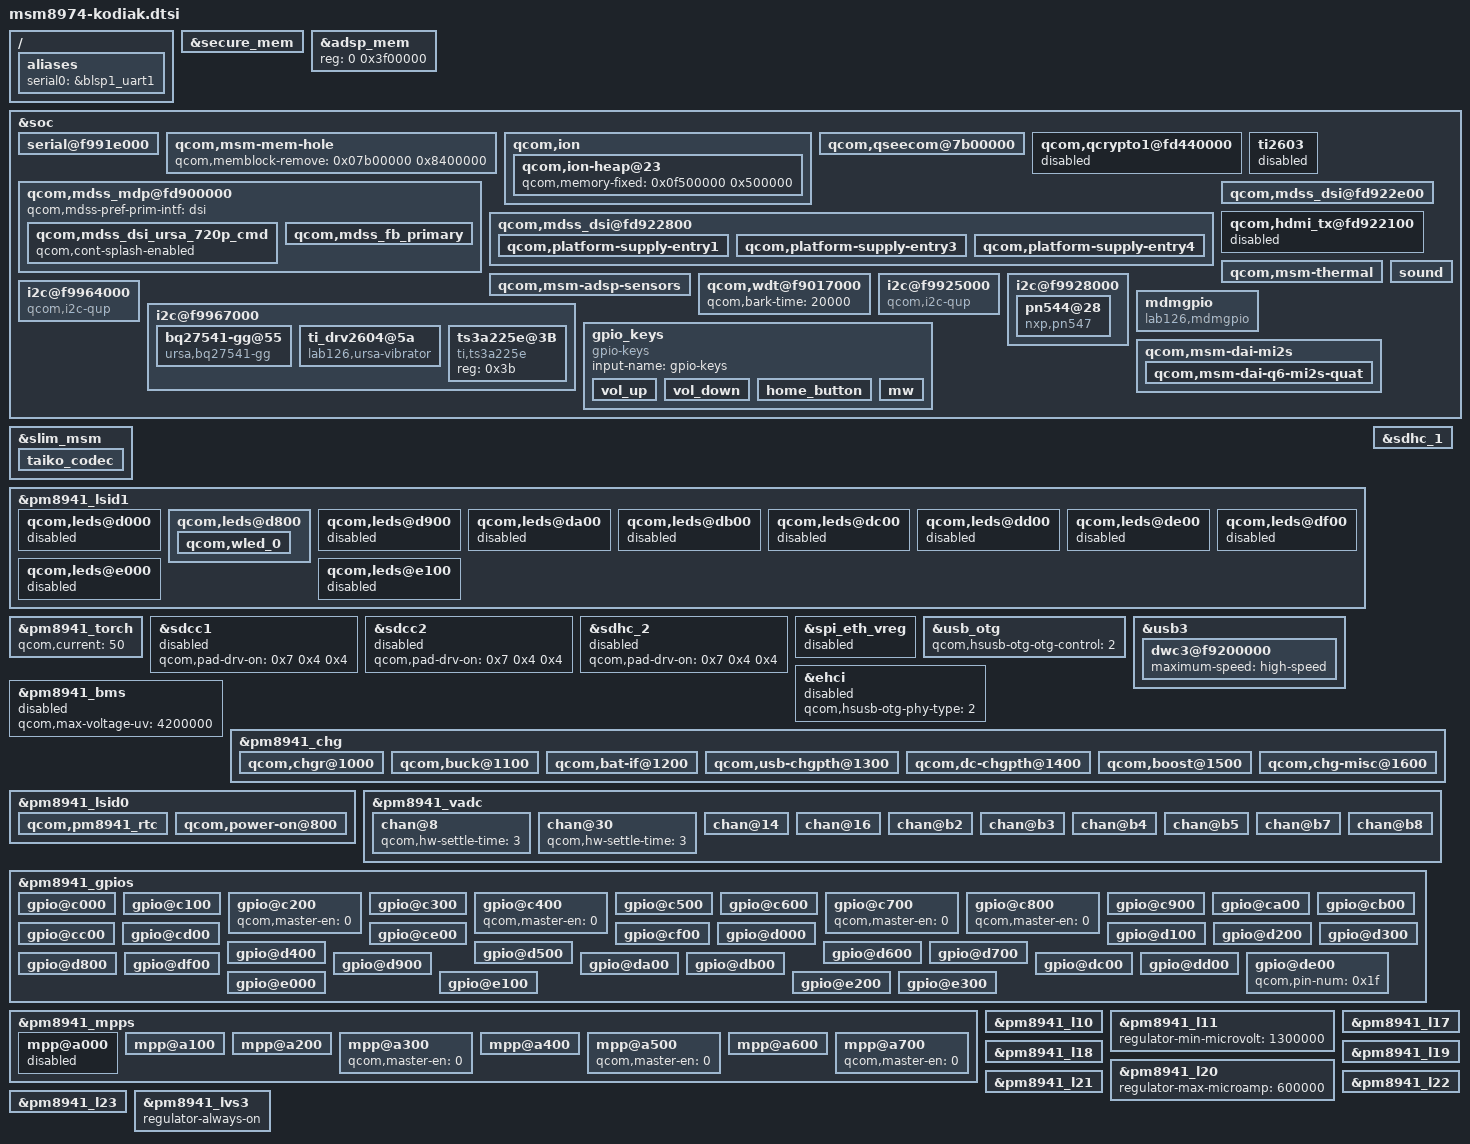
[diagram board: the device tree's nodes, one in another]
/* Copyright (c) 2012-2014, The Linux Foundation. All rights reserved.
 *
 * This program is free software; you can redistribute it and/or modify
 * it under the terms of the GNU General Public License version 2 and
 * only version 2 as published by the Free Software Foundation.
 *
 * This program is distributed in the hope that it will be useful,
 * but WITHOUT ANY WARRANTY; without even the implied warranty of
 * MERCHANTABILITY or FITNESS FOR A PARTICULAR PURPOSE.  See the
 * GNU General Public License for more details.
 */

/include/ "msm8974-camera-sensor-kodiak.dtsi"
/include/ "msm8974-leds.dtsi"
/include/ "msm8974-regulator.dtsi"
/include/ "dsi-panel-ursa-720p-cmd.dtsi"

/ {
	aliases {
		serial0 = &blsp1_uart1;
	};
};

&secure_mem {
	linux,reserve-region;
	reg = <0 0x9d00000>;
};

&adsp_mem {
	reg = <0 0x3f00000>;
};

&soc {
	serial@f991e000 {
		status = "ok";
		qcom,config-gpio = <2>;
		qcom,tx-gpio = <&msmgpio 4 0x00>;
		qcom,rx-gpio = <&msmgpio 5 0x00>;
	};

	qcom,msm-mem-hole {
		qcom,memblock-remove = <0x07b00000 0x8400000>; /* Address and Size of Hole */
	};

	qcom,ion {
		qcom,ion-heap@23 { /* OTHER PIL HEAP */
			qcom,memory-fixed = <0x0f500000 0x500000>;
		};
	};

	qcom,qseecom@7b00000 {
		/delete-property/ qcom,support-fde;
		/delete-property/ qcom,support-pfe;
		/delete-property/ qcom,file-encrypt-pipe-pair;
	};

	qcom,qcrypto1@fd440000 {
		status = "disabled";
	};

	ti2603 {
		status = "disabled";
	};

	qcom,mdss_mdp@fd900000 {
		qcom,mdss-pref-prim-intf = "dsi";

		qcom,mdss_dsi_ursa_720p_cmd {
			qcom,cont-splash-enabled;
		};

		qcom,mdss_fb_primary {
			qcom,memory-reservation-type = "EBI1";
			qcom,memory-reservation-size = <0x800000>;
		};
	};

	qcom,mdss_dsi@fd922800 {
		qcom,dsi-pref-prim-pan = <&dsi_ursa_720p_cmd>;
		qcom,platform-enable-gpio = <&msmgpio 58 0>;
		qcom,platform-touch-rst-gpio = <&msmgpio 60 0>;
		qcom,platform-lane-config = [00 00 00 00 00 00 00 01 97
			00 00 00 00 05 00 00 01 97
			00 00 00 00 0a 00 00 01 97
			00 00 00 00 0f 00 00 01 97
			00 c0 00 00 00 00 00 01 bb];
		vddio_panel-supply = <&pm8941_lvs2>;

		qcom,platform-supply-entry1 {
			qcom,supply-min-voltage = <3150000>;
			qcom,supply-max-voltage = <3150000>;
		};

		qcom,platform-supply-entry3 {
			qcom,supply-name = "vddio_panel";
			qcom,supply-min-voltage = <0>;
			qcom,supply-max-voltage = <0>;
			qcom,supply-enable-load = <0>;
			qcom,supply-disable-load = <0>;
			qcom,supply-pre-on-sleep = <0>;
			qcom,supply-post-on-sleep = <0>;
			qcom,supply-pre-off-sleep = <0>;
			qcom,supply-post-off-sleep = <0>;
		};

		qcom,platform-supply-entry4 {
			qcom,supply-name = "vdda";
			qcom,supply-min-voltage = <1200000>;
			qcom,supply-max-voltage = <1200000>;
			qcom,supply-enable-load = <100000>;
			qcom,supply-disable-load = <100>;
			qcom,supply-pre-on-sleep = <0>;
			qcom,supply-post-on-sleep = <0>;
			qcom,supply-pre-off-sleep = <0>;
			qcom,supply-post-off-sleep = <0>;
		};
	};

	qcom,mdss_dsi@fd922e00 {
		qcom,platform-lane-config = [00 00 00 00 00 00 00 01 97
			00 00 00 00 05 00 00 01 97
			00 00 00 00 0a 00 00 01 97
			00 00 00 00 0f 00 00 01 97
			00 c0 00 00 00 00 00 01 bb];
	};

	qcom,hdmi_tx@fd922100 {
		status = "disabled";
	};

	qcom,msm-thermal {
		qcom,limit-temp = <90>;
		qcom,core-limit-temp = <105>;
		qcom,core-temp-hysteresis = <15>;
	};

	qcom,msm-adsp-sensors {
		qcom,src-id = <11>;
		qcom,dst-id = <604>;
		qcom,ab = <32505856>;
		qcom,ib = <32505856>;
	};

	qcom,wdt@f9017000 {
		qcom,bark-time = <20000>;
	};

	i2c@f9925000 { /* BLSP-1 QUP-3 */
		cell-index = <3>;
		compatible = "qcom,i2c-qup";
		reg = <0xf9925000 0x1000>;
		#address-cells = <1>;
		#size-cells = <0>;
		reg-names = "qup_phys_addr";
		interrupts = <0 97 0>;
		interrupt-names = "qup_err_intr";
		qcom,i2c-bus-freq = <400000>;
		qcom,i2c-src-freq = <19200000>;
	};

	i2c@f9928000 { /* BLSP-1 QUP-6 */
		cell-index = <6>;
		qcom,i2c-src-freq = <50000000>;
		/delete-property/ qcom,master-id;
		/delete-property/ qcom,scl-gpio;
		/delete-property/ qcom,sda-gpio;

		pn544@28 {
			compatible = "nxp,pn547";
			reg = <0x28>;
			interrupt-parent = <&msmgpio>;
			interrupts = <59 0x2>, <86 0x3>;
			nxp,irq-gpio = <&msmgpio 59 0x00>;
			nxp,clk-req-gpio = <&msmgpio 86 0x00>;
			nxp,dload-gpio = <&pm8941_gpios 32 0x00>;
			nxp,enable-gpio = <&pm8941_gpios 7 0x00>;
			nxp,pvdd-supply = <&pm8941_l10>;
			nxp,pmuvcc-supply = <&pm8941_l9>;
		};
	};

	i2c@f9964000 { /* BLSP-2 QUP-2 */
		cell-index = <8>;
		compatible = "qcom,i2c-qup";
		reg = <0xf9964000 0x1000>;
		#address-cells = <1>;
		#size-cells = <0>;
		reg-names = "qup_phys_addr";
		interrupts = <0 102 0>;
		interrupt-names = "qup_err_intr";
		qcom,i2c-bus-freq = <400000>;
		qcom,i2c-src-freq = <50000000>;
	};

	i2c@f9967000 {
		bq27541-gg@55 {
			compatible = "ursa,bq27541-gg";
			reg = <0x55>;
			spmi-dev-container;
			ursa,use-voltage-soc = <0>;
			ursa,gg-snapshot-sec = <300>;
			ursa,gg-status-wake-sec = <3>;
			ursa,gg-status-sleep-real-sec = <1200>;
			ursa,info-shutoff-mv = <3250>;
			ursa,info-alt-shutoff-mv = <3100>;
			ursa,mib-charge-mv = <4350>;
			ursa,mib-capacity-mah = <2360>;
			ursa,mib-charge-rate = <7>;
			ursa,mib-taper-ma = <80>;
			ursa,limit-temp-hi-dk = <3332>;
			ursa,limit-temp-lo-dk = <2732>;
			ursa,limit-volt-hi-mv = <0>;
			ursa,limit-volt-lo-mv = <0>;
			ursa,limit-temp-hi-shutdown-dk = <3332>;
			ursa,limit-volt-lo-shutdown-mv = <3000>;
			qcom,gg-vadc = <&pm8941_vadc>;
			qcom,gg-iadc = <&pm8941_iadc>;
			status = "ok";
		};

		ti_drv2604@5a {
			compatible = "lab126,ursa-vibrator";
			reg = <0x5a>;
			gpios = <&pm8941_gpios 24 0>, <&pm8941_gpios 25 0>;
			ursa,max-duration-ms = <60000>;
			ursa,pwm-channel-id = <2>;
			ursa,pwm-duty-cycle = <95>;
			ursa,pwm-period-us = <50>;
			ursa,vib-init-duration = <0>;
		};

		ts3a225e@3B {
			compatible = "ti,ts3a225e";
			reg = <0x3b>;
		};
	};

	mdmgpio {
		compatible = "lab126,mdmgpio";
		gpios = <&msmgpio 100 0>;
		interrupt-parent = <&msmgpio>;
		interrupts = <100 0>;
	};

	gpio_keys {
		compatible = "gpio-keys";
		input-name = "gpio-keys";

		vol_up {
			label = "volume_up";
			gpios = <&pm8941_gpios 4 0x1>;
			linux,input-type = <1>;
			linux,code = <115>;
			gpio-key,wakeup;
			debounce-interval = <15>;
		};

		vol_down {
			label = "volume_down";
			gpios = <&pm8941_gpios 1 0x1>;
			linux,input-type = <1>;
			linux,code = <114>;
			gpio-key,wakeup;
			debounce-interval = <15>;
		};

		home_button {
			label = "home_button";
			gpios = <&pm8941_gpios 6 0x1>;
			linux,input-type = <1>;
			linux,code = <102>;
			gpio-key,wakeup;
			debounce-interval = <15>;
		};

		mw {
			label = "magic_window";
			gpios = <&pm8941_gpios 2 0x1>;
			linux,input-type = <1>;
			linux,code = <358>;
			gpio-key,wakeup;
			debounce-interval = <15>;
		};
	};

	sound {
		qcom,model = "msm8974-taiko-mtp-snd-card";
		qcom,audio-routing =
			"RX_BIAS", "MCLK",
			"LDO_H", "MCLK",
			"AMIC1", "MIC BIAS1 Internal1",
			"MIC BIAS1 Internal1", "Handset Mic",
			"AMIC2", "MIC BIAS2 External",
			"MIC BIAS2 External", "Headset Mic",
			"AMIC3", "MIC BIAS2 External",
			"MIC BIAS2 External", "ANCRight Headset Mic",
			"AMIC4", "MIC BIAS2 External",
			"MIC BIAS2 External", "ANCLeft Headset Mic",
			"DMIC1", "MIC BIAS1 External",
			"MIC BIAS1 External", "Digital Mic1",
			"DMIC2", "MIC BIAS1 External",
			"MIC BIAS1 External", "Digital Mic2",
			"DMIC3", "MIC BIAS3 External",
			"MIC BIAS3 External", "Digital Mic3",
			"DMIC4", "MIC BIAS4 External",
			"MIC BIAS4 External", "Digital Mic4",
			"DMIC5", "MIC BIAS4 External",
			"MIC BIAS4 External", "Digital Mic5",
			"DMIC6", "MIC BIAS4 External",
			"MIC BIAS4 External", "Digital Mic6";
		qcom,cdc-micbias2-headset-only;
		qcom,mbhc-gpio-level-insert = <0>;
	};

	qcom,msm-dai-mi2s {
		qcom,msm-dai-q6-mi2s-quat {
			qcom,msm-dai-q6-mi2s-dev-id = <1>;
			qcom,msm-mi2s-tx-lines = <0>;
		};
	};
};

&slim_msm {
	taiko_codec {
		qcom,cdc-micbias-cfilt2-mv = <2700>;
		qcom,cdc-micbias-cfilt3-mv = <1800>;
		qcom,cdc-micbias3-cfilt-sel = <0x0>;
		qcom,cdc-micbias4-cfilt-sel = <0x0>;
		qcom,cdc-micbias1-ext-cap;
		qcom,cdc-micbias3-ext-cap;
		qcom,cdc-micbias4-ext-cap;
		qcom,cdc-dmic-sample-rate = <2400000>;
		/delete-property/ cdc-vdd-spkdrv-supply;
		/delete-property/ qcom,cdc-vdd-spkdrv-voltage;
		/delete-property/ qcom,cdc-vdd-spkdrv-current;
		/delete-property/ qcom,cdc-on-demand-supplies;
		/delete-property/ qcom,cdc-micbias2-ext-cap;
	};
};

&pm8941_lsid1 {
	qcom,leds@d000 {
		status = "disabled";
	};

	qcom,leds@d800 {
		status = "okay";
		qcom,wled_0 {
			label = "wled";
			linux,name = "wled:backlight";
			linux,default-trigger = "bkl-trigger";
			qcom,cs-out-en;
			qcom,op-fdbck = <1>;
			qcom,default-state = "off";
			qcom,max-current = <18>;
			qcom,ctrl-delay-us = <0>;
			qcom,boost-curr-lim = <3>;
			qcom,cp-sel = <0>;
			qcom,switch-freq = <11>;
			qcom,ovp-val = <0>;
			qcom,num-strings = <1>;
			qcom,id = <0>;
		};
	};

	qcom,leds@d900 {
		status = "disabled";
	};

	qcom,leds@da00 {
		status = "disabled";
	};

	qcom,leds@db00 {
		status = "disabled";
	};

	qcom,leds@dc00 {
		status = "disabled";
	};

	qcom,leds@dd00 {
		status = "disabled";
	};

	qcom,leds@de00 {
		status = "disabled";
	};

	qcom,leds@df00 {
		status = "disabled";
	};

	qcom,leds@e000 {
		status = "disabled";
	};

	qcom,leds@e100 {
		status = "disabled";
	};
};

&pm8941_torch {
	qcom,current = <50>;
};

&sdcc1 {
	status = "disabled";
	qcom,pad-drv-on = <0x7 0x4 0x4>; /* 16mA, 10mA, 10mA */
};

&sdcc2 {
	status = "disabled";
	qcom,pad-drv-on = <0x7 0x4 0x4>; /* 16mA, 10mA, 10mA */
};

&sdhc_1 {
	vdd-supply = <&pm8941_l20>;
	vdd-io-supply = <&pm8941_s3>;

	qcom,vdd-always-on;
	qcom,vdd-lpm-sup;
	qcom,vdd-voltage-level = <2950000 2950000>;
	qcom,vdd-current-level = <800 500000>;

	qcom,vdd-io-always-on;
	qcom,vdd-io-voltage-level = <1800000 1800000>;
	qcom,vdd-io-current-level = <250 154000>;

	qcom,pad-pull-on = <0x0 0x3 0x3>; /* no-pull, pull-up, pull-up */
	qcom,pad-pull-off = <0x0 0x3 0x3>; /* no-pull, pull-up, pull-up */
	qcom,pad-drv-on = <0x5 0x7 0x7>; /* 12mA, 16mA, 16mA */
	qcom,pad-drv-off = <0x0 0x0 0x0>; /* 2mA, 2mA, 2mA */

	qcom,nonremovable;
	/delete-property/ qcom,dat1-mpm-int;
	status = "ok";
};

&sdhc_2 {
	qcom,pad-drv-on = <0x7 0x4 0x4>; /* 16mA, 10mA, 10mA */
	/delete-property/ qcom,dat1-mpm-int;
	status = "disabled";
};

&spi_eth_vreg {
	status = "disabled";
};

&usb_otg {
	qcom,hsusb-otg-otg-control = <2>;
};

&usb3 {
	interrupts = <0>;
	qcom,otg-capability;
	qcom,dwc-hsphy-init = <0x00d19564>;

	dwc3@f9200000 {
		maximum-speed = "high-speed";
	};
};

&ehci {
	qcom,hsusb-otg-phy-type = <2>;
	status = "disabled";
};

&pm8941_bms {
	qcom,max-voltage-uv = <4200000>;
	status = "disabled";
};

&pm8941_chg {
	status = "ok";

	qcom,vddsafe-mv = <4350>;
	qcom,vinmin-mv = <4350>;
	qcom,ibatmax-ma = <1210>;
	qcom,thermal-mitigation = <1210 700 350 200 0>;
	qcom,cool-bat-mv = <4350>;
	qcom,ibatmax-warm-ma = <726>;
	qcom,ibatmax-cool-ma = <484>;
	qcom,vbatdet-delta-mv = <50>;
	qcom,resume-soc = <97>;
	qcom,tchg-mins = <480>;
	qcom,bpd-detection = "bpd_thm_id";
	qcom,maxinput-dc-ma = <0>;
	qcom,maxinput-usb-ma = <0>;
	qcom,batt-hot-percentage = <25>;
	qcom,batt-cold-percentage = <80>;

	qcom,chgr@1000 {
		status = "ok";
	};

	qcom,buck@1100 {
		status = "ok";
	};

	qcom,bat-if@1200 {
		status = "ok";
	};

	qcom,usb-chgpth@1300 {
		status = "ok";
	};

	qcom,dc-chgpth@1400 {
		status = "ok";
	};

	qcom,boost@1500 {
		status = "ok";
	};

	qcom,chg-misc@1600 {
		status = "ok";
	};
};

&pm8941_lsid0 {
	qcom,pm8941_rtc {
		qcom,qpnp-rtc-write = <1>;
		qcom,qpnp-rtc-alarm-pwrup = <0>;
	};

	qcom,power-on@800 {
		interrupts = <0x0 0x8 0x0>,
			     <0x0 0x8 0x1>,
			     <0x0 0x8 0x3>,
			     <0x0 0x8 0x4>,
			     <0x0 0x8 0x5>;
		interrupt-names = "kpdpwr", "resin", "kpdpwr-bark",
				  "resin-bark", "kpdpwr-resin-bark";
	};
};

&pm8941_vadc {
	chan@8 {
		qcom,hw-settle-time = <3>;
	};

	chan@30 {
		qcom,hw-settle-time = <3>;
	};

	chan@14 {
		label = "peninsula_therm";
		reg = <0x14>;
		qcom,decimation = <0>;
		qcom,pre-div-channel-scaling = <0>;
		qcom,calibration-type = "ratiometric";
		qcom,scale-function = <10>;
		qcom,hw-settle-time = <0xf>;
		qcom,fast-avg-setup = <0>;
	};

	chan@16 {
		label = "flash_ntc";
		reg = <0x16>;
		qcom,decimation = <0>;
		qcom,pre-div-channel-scaling = <0>;
		qcom,calibration-type = "ratiometric";
		qcom,scale-function = <10>;
		qcom,hw-settle-time = <0xf>;
		qcom,fast-avg-setup = <0>;
	};

	chan@b2 {
		qcom,scale-function = <10>;
		qcom,hw-settle-time = <3>;
	};

	chan@b3 {
		qcom,scale-function = <10>;
		qcom,hw-settle-time = <3>;
	};

	chan@b4 {
		qcom,scale-function = <10>;
		qcom,hw-settle-time = <3>;
	};

	chan@b5 {
		qcom,scale-function = <10>;
		qcom,hw-settle-time = <0xf>;
	};

	/delete-node/ chan@b6;

	chan@b7 {
		label = "pa_therm1_IGNORE";
		qcom,hw-settle-time = <3>;
	};

	chan@b8 {
		qcom,scale-function = <10>;
		qcom,hw-settle-time = <3>;
	};
};

&pm8941_gpios {
	gpio@c000 { /* GPIO 1 */
		qcom,mode = <0>;
		qcom,pull = <0>;
		qcom,vin-sel = <2>;
		qcom,src-sel = <0>;
	};

	gpio@c100 { /* GPIO 2 */
		qcom,mode = <0>;
		qcom,pull = <0>;
		qcom,vin-sel = <2>;
		qcom,src-sel = <0>;
	};

	gpio@c200 { /* GPIO 3 */
		qcom,master-en = <0>;
	};

	gpio@c300 { /* GPIO 4 */
		qcom,mode = <0>;
		qcom,pull = <0>;
		qcom,vin-sel = <2>;
		qcom,src-sel = <0>;
	};

	gpio@c400 { /* GPIO 5 */
		qcom,master-en = <0>;
	};

	gpio@c500 { /* GPIO 6 */
		qcom,mode = <0>;
		qcom,pull = <5>;
		qcom,vin-sel = <2>;
		qcom,src-sel = <0>;
	};

	gpio@c600 { /* GPIO 7 */
		qcom,mode = <1>;
		qcom,output-type = <0>;
		qcom,pull = <5>;
		qcom,vin-sel = <2>;
		qcom,src-sel = <0>;
		qcom,out-strength = <3>;
	};

	gpio@c700 { /* GPIO 8 */
		qcom,master-en = <0>;
	};

	gpio@c800 { /* GPIO 9 */
		qcom,master-en = <0>;
	};

	gpio@c900 { /* GPIO None */
		qcom,pin-num = <0xa>;
		qcom,master-en = <0>;
	};

	gpio@ca00 { /* GPIO None */
		qcom,pin-num = <0xb>;
		qcom,master-en = <0>;
	};

	gpio@cb00 { /* GPIO None */
		qcom,pin-num = <0xc>;
		qcom,master-en = <0>;
	};

	gpio@cc00 { /* GPIO None */
		qcom,pin-num = <0xd>;
		qcom,master-en = <0>;
	};

	gpio@cd00 { /* GPIO None */
		qcom,pin-num = <0xe>;
		qcom,master-en = <0>;
	};

	gpio@ce00 { /* GPIO None */
		qcom,pin-num = <0xf>;
		qcom,mode = <1>;
		qcom,output-type = <0>;
		qcom,pull = <5>;
		qcom,vin-sel = <2>;
		qcom,out-strength = <1>;
		qcom,src-sel = <2>;
		qcom,master-en = <1>;
	};

	gpio@cf00 { /* GPIO None */
		qcom,pin-num = <0x10>;
		qcom,master-en = <0>;
	};

	gpio@d000 { /* GPIO None */
		qcom,pin-num = <0x11>;
		qcom,master-en = <0>;
	};

	gpio@d100 { /* GPIO None */
		qcom,pin-num = <0x12>;
		qcom,master-en = <0>;
	};

	gpio@d200 { /* GPIO None */
		qcom,pin-num = <0x13>;
		qcom,mode = <1>;
		qcom,output-type = <0>;
		qcom,pull = <5>;
		qcom,vin-sel = <2>;
		qcom,out-strength = <3>;
		qcom,src-sel = <0>;
	};

	gpio@d300 { /* GPIO None */
		qcom,pin-num = <0x14>;
		qcom,master-en = <0>;
	};

	gpio@d400 { /* GPIO None */
		qcom,pin-num = <0x15>;
		qcom,mode = <1>;
		qcom,output-type = <0>;
		qcom,pull = <5>;
		qcom,vin-sel = <2>;
		qcom,out-strength = <3>;
		qcom,src-sel = <2>;
	};

	gpio@d500 { /* GPIO None */
		qcom,pin-num = <0x16>;
		qcom,master-en = <0>;
	};

	gpio@d600 { /* GPIO None */
		qcom,pin-num = <0x17>;
		qcom,master-en = <0>;
	};

	gpio@d700 { /* GPIO None */
		qcom,pin-num = <0x18>;
		qcom,mode = <1>;
		qcom,output-type = <0>;
		qcom,pull = <5>;
		qcom,vin-sel = <2>;
		qcom,out-strength = <3>;
		qcom,src-sel = <0>;
	};

	gpio@d800 { /* GPIO None */
		qcom,pin-num = <0x19>;
		qcom,mode = <1>;
		qcom,output-type = <0>;
		qcom,pull = <5>;
		qcom,vin-sel = <2>;
		qcom,out-strength = <3>;
		qcom,src-sel = <3>;
	};

	gpio@d900 { /* GPIO None */
		qcom,pin-num = <0x1a>;
		qcom,master-en = <0>;
	};

	gpio@da00 { /* GPIO None */
		qcom,pin-num = <0x1b>;
		qcom,mode = <0>;
		qcom,pull = <4>;
		qcom,vin-sel = <2>;
		qcom,src-sel = <2>;
	};

	gpio@db00 { /* GPIO None */
		qcom,pin-num = <0x1c>;
		qcom,mode = <0>;
		qcom,pull = <4>;
		qcom,vin-sel = <2>;
		qcom,src-sel = <2>;
	};

	gpio@dc00 { /* GPIO None */
		qcom,pin-num = <0x1d>;
		qcom,master-en = <0>;
	};

	gpio@dd00 { /* GPIO None */
		qcom,pin-num = <0x1e>;
		qcom,master-en = <0>;
	};

	gpio@de00 { /* GPIO None */
		qcom,pin-num = <0x1f>;
	};

	gpio@df00 { /* GPIO None */
		qcom,pin-num = <0x20>;
		qcom,mode = <1>;
		qcom,output-type = <0>;
		qcom,pull = <5>;
		qcom,vin-sel = <2>;
		qcom,src-sel = <0>;
		qcom,out-strength = <3>;
	};

	gpio@e000 { /* GPIO None */
		qcom,pin-num = <0x21>;
		qcom,master-en = <0>;
	};

	gpio@e100 { /* GPIO None */
		qcom,pin-num = <0x22>;
		qcom,master-en = <0>;
	};

	gpio@e200 { /* GPIO None */
		qcom,pin-num = <0x23>;
		qcom,master-en = <0>;
	};

	gpio@e300 { /* GPIO None */
		qcom,pin-num = <0x24>;
		qcom,master-en = <0>;
	};
};

&pm8941_mpps {
	mpp@a000 { /* MPP 1 */
		status = "disabled";
	};

	mpp@a100 { /* MPP 2 */

	};

	mpp@a200 { /* MPP 3 */

	};

	mpp@a300 { /* MPP 4 */
		qcom,master-en = <0>;
	};

	mpp@a400 { /* MPP 5 */
		qcom,mode = <4>;
		qcom,src-sel = <0>;
		qcom,master-en = <1>;
		qcom,ain-route = <0>;
		qcom,invert = <1>;
	};

	mpp@a500 { /* MPP 6 */
		qcom,master-en = <0>;
	};

	mpp@a600 { /* MPP 7 */
		qcom,mode = <4>;
		qcom,src-sel = <0>;
		qcom,master-en = <1>;
		qcom,ain-route = <2>;
		qcom,invert = <1>;
	};

	mpp@a700 { /* MPP 8 */
		qcom,master-en = <0>;
	};
};

&pm8941_l10 {
	regulator-max-microvolt = <1800000>;
	regulator-max-microamp = <150000>;
	qcom,init-voltage = <1800000>;
};

&pm8941_l11 {
	regulator-min-microvolt = <1300000>;
};

&pm8941_l17 {
	regulator-min-microvolt = <3000000>;
	regulator-max-microamp = <300000>;
	qcom,init-voltage = <3000000>;
	regulator-always-on;
};

&pm8941_l18 {
	regulator-min-microvolt = <1800000>;
	regulator-max-microvolt = <1800000>;
	regulator-max-microamp = <300000>;
	qcom,init-voltage = <1800000>;
	regulator-always-on;
};

&pm8941_l19 {
	regulator-max-microvolt = <2900000>;
	regulator-max-microamp = <600000>;
};

&pm8941_l20 {
	regulator-max-microamp = <600000>;
};

&pm8941_l21 {
	regulator-min-microvolt = <2800000>;
	regulator-max-microvolt = <2850000>;
	regulator-max-microamp = <600000>;
	qcom,init-voltage = <2800000>;
};

&pm8941_l22 {
	regulator-min-microvolt = <3150000>;
	regulator-max-microvolt = <3150000>;
	regulator-max-microamp = <300000>;
	qcom,init-voltage = <3150000>;
};

&pm8941_l23 {
	regulator-min-microvolt = <2800000>;
	regulator-max-microvolt = <2800000>;
	regulator-max-microamp = <300000>;
	qcom,init-voltage = <2800000>;
};

&pm8941_lvs3 {
	regulator-always-on;
};
